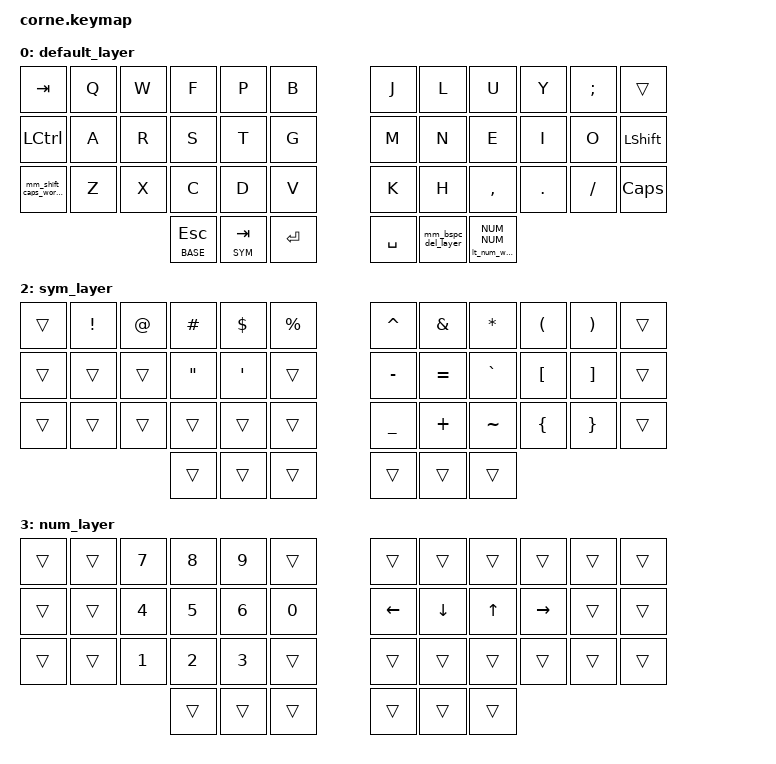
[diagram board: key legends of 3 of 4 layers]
/*

 * Copyright (c) 2020 The ZMK Contributors
 *
 * SPDX-License-Identifier: MIT
 */

// ZMK INCLUDES
#include <behaviors.dtsi>
#include <dt-bindings/zmk/bt.h>
#include <dt-bindings/zmk/keys.h>

// PERSONAL INCLUDES
#include "includes/behaviours_homerow_mods.dtsi"
#include "includes/behaviours_mod_morph.dtsi"
#include "includes/behaviours_other.dtsi"
#include "includes/settings.dtsi"

// DEFINE LAYER NUMBERS
#define BASE 1
#define SYM 2
#define NUM 3

/ {

    keymap {
        compatible = "zmk,keymap";

        default_layer {
            bindings = <
            
//╭───────────────────────────┬───────────────────────────┬───────────────────────────┬───────────────────────────┬───────────────────────────┬───────────────────────────╮  ╭───────────────────────────┬───────────────────────────┬───────────────────────────┬───────────────────────────┬───────────────────────────┬───────────────────────────╮
//│                           │ Q                         │ W                         │ F                         │ P                         │ B                         │  │ J                         │ L                         │ U                         │ Y                         │ ; :                       │                           │ 
    &kp TAB                      &kp Q                       &kp W                       &kp F                       &kp P                       &kp B                         &kp J                       &kp L                       &kp U                       &kp Y                       &kp SEMICOLON                      &trans
//├───────────────────────────┼───────────────────────────┼───────────────────────────┼───────────────────────────┼───────────────────────────┼───────────────────────────┤  ├───────────────────────────┼───────────────────────────┼───────────────────────────┼───────────────────────────┼───────────────────────────┼───────────────────────────┤
//│                           │  A              │         │  R                        │ S                         │  T                        │ G                         │  │ M                         │  N                        │  E                        │  I                        │  O                        │
    &kp LCTRL                   &kp A                        &kp R                      &kp S                       &kp T                       &kp G                          &kp M                       &kp N                       &kp E                       &kp I                       &kp O                       &kp LSHIFT
//├───────────────────────────┼───────────────────────────┼───────────────────────────┼───────────────────────────┼───────────────────────────┼───────────────────────────┤  ├───────────────────────────┼───────────────────────────┼───────────────────────────┼───────────────────────────┼───────────────────────────┼───────────────────────────┤
//│ STICKY SHIFT + CAPS WORD  │ Z                         │ X                         │ C                         │ D                         │ V                         │  │ K                         │ H                         │ , <                       │ . >                       │ / ?                       │                           │
    &mm_shift_caps_word_l       &kp Z                       &kp X                       &kp C                       &kp D                       &kp V                          &kp K                       &kp H                       &kp COMMA                   &kp DOT                     &kp FSLH                    &kp CAPSLOCK
//╰───────────────────────────┴───────────────────────────┴───────────────────────────┼───────────────────────────┼───────────────────────────┼───────────────────────────┤  ├───────────────────────────┼───────────────────────────┼───────────────────────────┼───────────────────────────┴───────────────────────────┴───────────────────────────╯
//                                                                                    │ BASE LAYOUT + ESC         │ TAB                       │ ENTER                     │  │ SPACE                     │ BSPPC + DEL + LAYER       │ NUM WORD                  │
                                                                                        &lt BASE ESC                &lt SYM TAB                 &kp ENTER                      &kp SPACE                   &mm_bspc_del_layer          &lt_num_word NUM NUM
//                                                                                    ╰───────────────────────────┴───────────────────────────┴───────────────────────────╯  ╰───────────────────────────┴───────────────────────────┴───────────────────────────╯

            >; 
        };

        lower_layer {
            bindings = <
&kp TAB     &kp N1        &kp N2        &kp N3        &kp N4        &kp N5          &kp N6    &kp N7    &kp N8    &kp N9     &kp N0  &kp BSPC
&bt BT_CLR  &bt BT_SEL 0  &bt BT_SEL 1  &bt BT_SEL 2  &bt BT_SEL 3  &bt BT_SEL 4    &kp LEFT 
&kp LSHFT   &trans        &trans        &trans        &trans        &trans          &trans    &trans    &trans    &trans     &trans  &trans
                                        &kp LGUI      &trans        &kp SPACE       &kp RET   &trans    &kp RALT
            >;
        };

        sym_layer {
            bindings = <
//╭──────────┬──────────┬──────────┬──────────┬──────────┬──────────╮   ╭──────────┬──────────┬──────────┬──────────┬──────────┬──────────╮
//│                !         @         #            $         %            ^               &         *      (           )
    &trans     &kp EXCL   &kp AT     &kp HASH   &kp DLLR   &kp PRCNT     &kp CARET  &kp AMPS   &kp ASTRK   &kp LPAR   &kp RPAR   &trans                                                                                              
//├──────────┼──────────┼──────────┼──────────┼──────────┼──────────┤   ├──────────┼──────────┼──────────┼──────────┼──────────┼──────────┤
//│          │          │          │   "      │    '     │          │   │  -       │  =       │     `    │  [       │    ]
    &trans     &trans     &trans     &kp DQT     &kp SQT      &trans      &kp MINUS  &kp EQUAL  &kp GRAVE   &kp LBKT  &kp RBKT    &trans
//├──────────┼──────────┼──────────┼──────────┼──────────┼──────────┤   ├──────────┼──────────┼──────────┼──────────┼──────────┼──────────┤
//│          │          │          │          │          │          │   │  _       │  +       │   ~      │   {      │   }
    &trans     &trans      &trans    &trans      &trans    &trans         &kp UNDER  &kp PLUS   &kp TILDE  &kp LBRC   &kp RBRC    &trans
//╰──────────┴──────────┴──────────┼──────────┼──────────┼──────────┤   ├──────────┼──────────┼──────────┼──────────┴──────────┴──────────╯
                                     &trans     &trans         &trans     &trans     &trans     &trans
//                                 ╰──────────┴──────────┴──────────╯   ╰──────────┴──────────┴──────────╯
                >;
        };
        
        num_layer {
            bindings = <
&trans                  &trans                &kp NUMBER_7              &kp NUMBER_8           &kp NUMBER_9                   &trans                 &trans                &trans                   &trans           &trans                &trans                 &trans
&trans                  &trans                &kp NUMBER_4              &kp NUMBER_5           &kp NUMBER_6                   &kp NUMBER_0           &kp LEFT_ARROW        &kp DOWN_ARROW           &kp UP_ARROW     &kp RIGHT_ARROW        &trans                &trans
&trans                  &trans                &kp NUMBER_1              &kp NUMBER_2           &kp NUMBER_3                   &trans                 &trans                &trans                   &trans           &trans                &trans                 &trans
                                                                        &trans                 &trans                         &trans                 &trans                &trans                   &trans 
            >;
        };

    };
};
